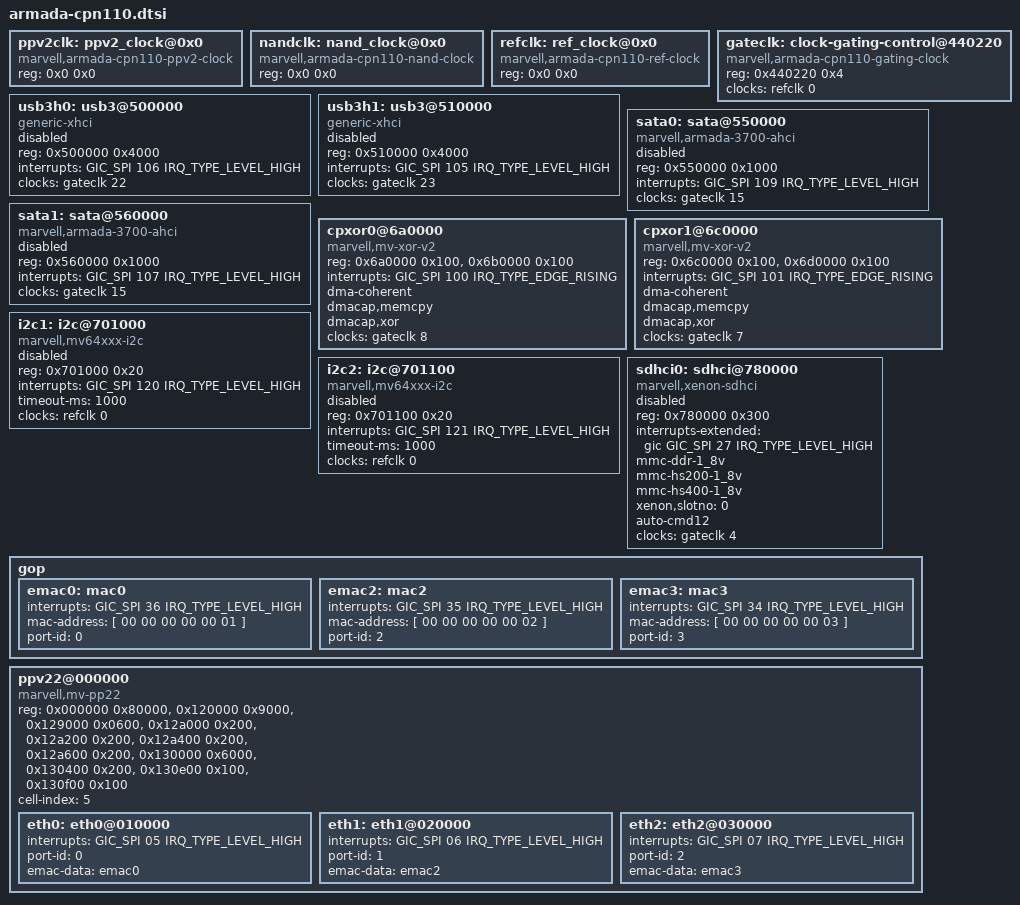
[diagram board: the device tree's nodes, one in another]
/****************************************************************************
* This program is free software: you can redistribute it and/or modify it
* under the terms of the GNU General Public License as published by the Free
* Software Foundation, either version 2 of the License, or any later version.
*
* This program is distributed in the hope that it will be useful,
* but WITHOUT ANY WARRANTY; without even the implied warranty of
* MERCHANTABILITY or FITNESS FOR A PARTICULAR PURPOSE.  See the
* GNU General Public License for more details.
*
* You should have received a copy of the GNU General Public License
* along with this program.  If not, see <http://www.gnu.org/licenses/>.
* ***************************************************************************
*/

/*
 * Generic Device Tree describing Marvell Armada CPN-110 devices
 */

ppv2clk: ppv2_clock@0x0 { /* no address - use fixed clock */
	compatible = "marvell,armada-cpn110-ppv2-clock";
	reg = <0x0 0x0>;
	#clock-cells = <1>;
};

nandclk: nand_clock@0x0 { /* no address - use fixed clock */
	compatible = "marvell,armada-cpn110-nand-clock";
	reg = <0x0 0x0>;
	#clock-cells = <1>;
};

refclk: ref_clock@0x0 { /* no address - use fixed clock */
	compatible = "marvell,armada-cpn110-ref-clock";
	reg = <0x0 0x0>;
	#clock-cells = <1>;
};

gateclk: clock-gating-control@440220 {
	compatible = "marvell,armada-cpn110-gating-clock";
	reg = <0x440220 0x4>;
	clocks = <&refclk 0>;
	#clock-cells = <1>;
};

usb3h0: usb3@500000 {
	compatible = "generic-xhci";
	reg = <0x500000 0x4000>;
	interrupts = <GIC_SPI 106 IRQ_TYPE_LEVEL_HIGH>;
	clocks = <&gateclk 22>;
	status = "disabled";
};

usb3h1: usb3@510000 {
	compatible = "generic-xhci";
	reg = <0x510000 0x4000>;
	interrupts = <GIC_SPI 105 IRQ_TYPE_LEVEL_HIGH>;
	clocks = <&gateclk 23>;
	status = "disabled";
};

sata0: sata@550000 {
	compatible = "marvell,armada-3700-ahci";
	reg = <0x550000 0x1000>;
	interrupts = <GIC_SPI 109 IRQ_TYPE_LEVEL_HIGH>;
	clocks = <&gateclk 15>;
	status = "disabled";
};

sata1: sata@560000 {
	compatible = "marvell,armada-3700-ahci";
	reg = <0x560000 0x1000>;
	interrupts = <GIC_SPI 107 IRQ_TYPE_LEVEL_HIGH>;
	clocks = <&gateclk 15>;
	status = "disabled";
};

cpxor0@6a0000 {
	compatible = "marvell,mv-xor-v2";
	reg = <0x6a0000 0x100>,
	      <0x6b0000 0x100>;
	interrupts = <GIC_SPI 100 IRQ_TYPE_EDGE_RISING>;
	dma-coherent;
	dmacap,memcpy;
	dmacap,xor;
	/*dmacap,pq;*/
	clocks = <&gateclk 8>;
};

cpxor1@6c0000 {
	compatible = "marvell,mv-xor-v2";
	reg = <0x6c0000 0x100>,
	      <0x6d0000 0x100>;
	interrupts = <GIC_SPI 101 IRQ_TYPE_EDGE_RISING>;
	dma-coherent;
	dmacap,memcpy;
	dmacap,xor;
	/*dmacap,pq;*/
	clocks = <&gateclk 7>;
};

i2c1: i2c@701000 {
	compatible = "marvell,mv64xxx-i2c";
	reg = <0x701000 0x20>;
	#address-cells = <1>;
	#size-cells = <0>;
	interrupts = <GIC_SPI 120 IRQ_TYPE_LEVEL_HIGH>;
	timeout-ms = <1000>;
	clocks = <&refclk 0>;
	status = "disabled";
};

i2c2: i2c@701100 {
	compatible = "marvell,mv64xxx-i2c";
	reg = <0x701100 0x20>;
	#address-cells = <1>;
	#size-cells = <0>;
	interrupts = <GIC_SPI 121 IRQ_TYPE_LEVEL_HIGH>;
	timeout-ms = <1000>;
	clocks = <&refclk 0>;
	status = "disabled";
};

sdhci0: sdhci@780000 {
	compatible = "marvell,xenon-sdhci";
	reg = <0x780000 0x300>;
	interrupts-extended = <&gic GIC_SPI 27 IRQ_TYPE_LEVEL_HIGH>;
	mmc-ddr-1_8v;
	mmc-hs200-1_8v;
	mmc-hs400-1_8v;
	xenon,slotno = <0>;
	auto-cmd12;
	clocks = <&gateclk 4>;
	status = "disabled";
};
gop {
	emac0: mac0 {
		interrupts = <GIC_SPI 36 IRQ_TYPE_LEVEL_HIGH>;  /* Link IRQ */
		mac-address = [ 00 00 00 00 00 01 ];
		port-id = <0>;
	};
	emac2: mac2 {
		interrupts = <GIC_SPI 35 IRQ_TYPE_LEVEL_HIGH>;  /* Link IRQ */
		mac-address = [ 00 00 00 00 00 02 ];
		port-id = <2>;
	};
	emac3: mac3 {		
		interrupts = <GIC_SPI 34 IRQ_TYPE_LEVEL_HIGH>;  /* Link IRQ */
		mac-address = [ 00 00 00 00 00 03 ];
		port-id = <3>;
	};
};
ppv22@000000 {
	compatible = "marvell,mv-pp22";
	reg = <0x000000 0x80000>, /* Packet Processor regs */
	      <0x120000 0x9000>, /* SERDES regs */
	      <0x129000 0x0600>, /* XMIB regs */
	      <0x12a000 0x200>,  /* LED regs */
	      <0x12a200 0x200>,  /* SMI regs */
	      <0x12a400 0x200>,  /* TAI regs */
	      <0x12a600 0x200>,  /* XSMI regs */
	      <0x130000 0x6000>, /* MSPG regs */	      
	      <0x130400 0x200>,  /* MSPG - XPCS regs */
	      <0x130e00 0x100>,  /* MSPG - GMAC regs */
	      <0x130f00 0x100>;  /* MSPG - XLG MAC regs */
	reg-names = "pp", "serdes", "xmib", "led", "smi", "tai", "xsmi", "mspg", "xpcs", "gmac", "xlg";	
	cell-index = <5>;
//	clocks = <&ppv2clk 0>, <&gateclk 18>;
//	clock-names = "pp_clk", "gop_clk";		
	status = "okay";
	eth0: eth0@010000 {
		interrupts = <GIC_SPI 05 IRQ_TYPE_LEVEL_HIGH>; /* TX/RX Interrupt */
		port-id = <0>;
		emac-data = <&emac0>;		
		status = "okay";
	};
	eth1: eth1@020000 {		
		interrupts = <GIC_SPI 06 IRQ_TYPE_LEVEL_HIGH>; /* TX/RX Interrupt */
		port-id = <1>;
		emac-data = <&emac2>;		
		status = "okay";
	};
	eth2: eth2@030000 {
		interrupts = <GIC_SPI 07 IRQ_TYPE_LEVEL_HIGH>; /* TX/RX Interrupt */
		port-id = <2>;
		emac-data = <&emac3>;		
		status = "okay";
	};
};
